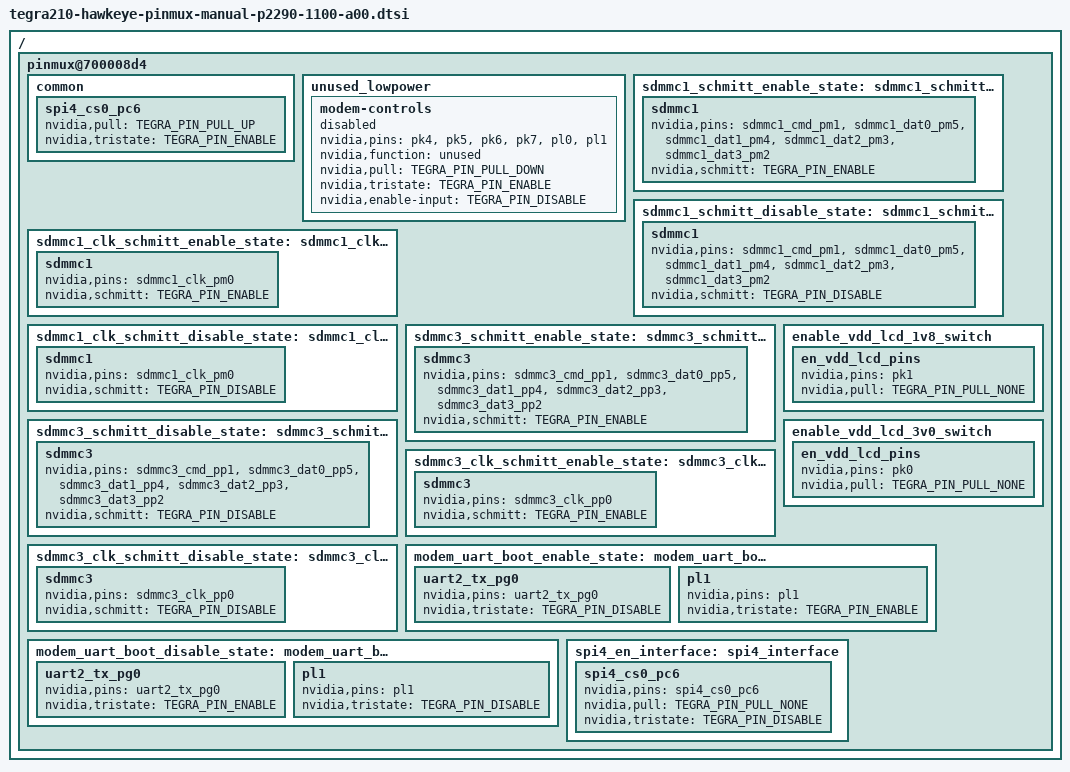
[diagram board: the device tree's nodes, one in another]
/*
 * Copyright (c) 2014-2015, NVIDIA CORPORATION.  All rights reserved.
 *
 * This program is free software; you can redistribute it and/or modify
 * it under the terms of the GNU General Public License as published by
 * the Free Software Foundation; either version 2 of the License, or
 * (at your option) any later version.
 *
 * This program is distributed in the hope that it will be useful, but WITHOUT
 * ANY WARRANTY; without even the implied warranty of MERCHANTABILITY or
 * FITNESS FOR A PARTICULAR PURPOSE.  See the GNU General Public License for
 * more details.
 *
 * You should have received a copy of the GNU General Public License along
 * with this program; if not, write to the Free Software Foundation, Inc.,
 * 51 Franklin Street, Fifth Floor, Boston, MA  02110-1301, USA.
 */

#include <dt-bindings/pinctrl/pinctrl-tegra.h>

/ {
	pinmux@700008d4 {
		/* Keep SPI4_CS0 to tristate default until master setup */
		common {
			spi4_cs0_pc6 {
				nvidia,pull = <TEGRA_PIN_PULL_UP>;
				nvidia,tristate = <TEGRA_PIN_ENABLE>;
			};
		};

		unused_lowpower {
			modem-controls {
				status = "disabled";
				nvidia,pins = "pk4", "pk5", "pk6", "pk7", "pl0", "pl1";
				nvidia,function = "unused";
				nvidia,pull = <TEGRA_PIN_PULL_DOWN>;
				nvidia,tristate = <TEGRA_PIN_ENABLE>;
				nvidia,enable-input = <TEGRA_PIN_DISABLE>;
			};
		};

		sdmmc1_schmitt_enable_state: sdmmc1_schmitt_enable {
			sdmmc1 {
				 nvidia,pins = "sdmmc1_cmd_pm1", "sdmmc1_dat0_pm5", "sdmmc1_dat1_pm4", "sdmmc1_dat2_pm3", "sdmmc1_dat3_pm2";
				 nvidia,schmitt = <TEGRA_PIN_ENABLE>;
			};
		};

		sdmmc1_schmitt_disable_state: sdmmc1_schmitt_disable {
			sdmmc1 {
				 nvidia,pins = "sdmmc1_cmd_pm1", "sdmmc1_dat0_pm5", "sdmmc1_dat1_pm4", "sdmmc1_dat2_pm3", "sdmmc1_dat3_pm2";
				 nvidia,schmitt = <TEGRA_PIN_DISABLE>;
			};
		};

		sdmmc1_clk_schmitt_enable_state: sdmmc1_clk_schmitt_enable {
			sdmmc1 {
				 nvidia,pins = "sdmmc1_clk_pm0";
				 nvidia,schmitt = <TEGRA_PIN_ENABLE>;
			};
		};

		sdmmc1_clk_schmitt_disable_state: sdmmc1_clk_schmitt_disable {
			sdmmc1 {
				 nvidia,pins = "sdmmc1_clk_pm0";
				 nvidia,schmitt = <TEGRA_PIN_DISABLE>;
			};
		};

		sdmmc3_schmitt_enable_state: sdmmc3_schmitt_enable {
			sdmmc3 {
				 nvidia,pins = "sdmmc3_cmd_pp1", "sdmmc3_dat0_pp5", "sdmmc3_dat1_pp4", "sdmmc3_dat2_pp3", "sdmmc3_dat3_pp2";
				 nvidia,schmitt = <TEGRA_PIN_ENABLE>;
			};
		};

		sdmmc3_schmitt_disable_state: sdmmc3_schmitt_disable {
			sdmmc3 {
				 nvidia,pins = "sdmmc3_cmd_pp1", "sdmmc3_dat0_pp5", "sdmmc3_dat1_pp4", "sdmmc3_dat2_pp3", "sdmmc3_dat3_pp2";
				 nvidia,schmitt = <TEGRA_PIN_DISABLE>;
			};
		};

		sdmmc3_clk_schmitt_enable_state: sdmmc3_clk_schmitt_enable {
			sdmmc3 {
				 nvidia,pins = "sdmmc3_clk_pp0";
				 nvidia,schmitt = <TEGRA_PIN_ENABLE>;
			};
		};

		sdmmc3_clk_schmitt_disable_state: sdmmc3_clk_schmitt_disable {
			sdmmc3 {
				 nvidia,pins = "sdmmc3_clk_pp0";
				 nvidia,schmitt = <TEGRA_PIN_DISABLE>;
			};
		};

		enable_vdd_lcd_1v8_switch: enable_vdd_lcd_1v8_switch {
			en_vdd_lcd_pins {
				nvidia,pins = "pk1";
				nvidia,pull = <TEGRA_PIN_PULL_NONE>;
			};
		};

		enable_vdd_lcd_3v0_switch: enable_vdd_lcd_3v0_switch {
			en_vdd_lcd_pins {
				nvidia,pins = "pk0";
				nvidia,pull = <TEGRA_PIN_PULL_NONE>;
			};
		};

		modem_uart_boot_enable_state: modem_uart_boot_enable {
			uart2_tx_pg0 {
				nvidia,pins = "uart2_tx_pg0";
				nvidia,tristate = <TEGRA_PIN_DISABLE>;
			};

			pl1 {
				nvidia,pins = "pl1";
				nvidia,tristate = <TEGRA_PIN_ENABLE>;
			};
		};

		modem_uart_boot_disable_state: modem_uart_boot_disable {
			uart2_tx_pg0 {
				nvidia,pins = "uart2_tx_pg0";
				nvidia,tristate = <TEGRA_PIN_ENABLE>;
			};

			pl1 {
				nvidia,pins = "pl1";
				nvidia,tristate = <TEGRA_PIN_DISABLE>;
			};
		};

		spi4_en_interface: spi4_interface {
			spi4_cs0_pc6 {
				nvidia,pins = "spi4_cs0_pc6";
				nvidia,pull = <TEGRA_PIN_PULL_NONE>;
				nvidia,tristate = <TEGRA_PIN_DISABLE>;
			};
		};
	};
};
